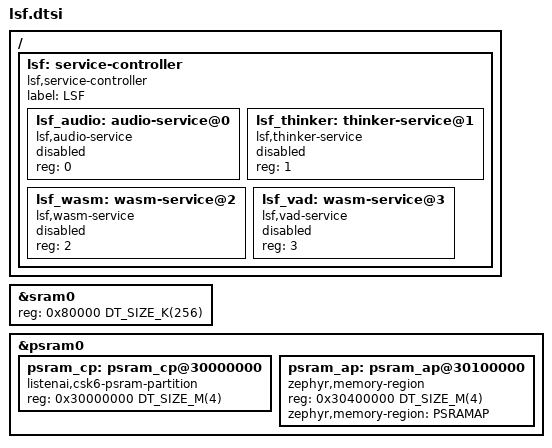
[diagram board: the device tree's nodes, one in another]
/*
 * Copyright(c) 2023 LISTENAI
 * SPDX-License-Identifier: Apache-2.0
 */

#include <mem.h>

/ {
	lsf: service-controller {
		compatible = "lsf,service-controller";
		#address-cells = <1>;
		#size-cells = <0>;
		label = "LSF";

		lsf_audio: audio-service@0 {
			compatible = "lsf,audio-service";
			reg = <0>;
			status = "disabled";
		};

		lsf_thinker: thinker-service@1 {
			compatible = "lsf,thinker-service";
			reg = <1>;
			status = "disabled";
		};

		lsf_wasm: wasm-service@2 {
			compatible = "lsf,wasm-service";
			reg = <2>;
			status = "disabled";
		};

		lsf_vad: wasm-service@3 {
			compatible = "lsf,vad-service";
			reg = <3>;
			status = "disabled";
		};
	};
};

/delete-node/ &psram_ap;
/delete-node/ &psram_cp;
/delete-node/ &psram_share;

&sram0 {
	reg = <0x80000 DT_SIZE_K(256)>;
};

&psram0 {
	psram_cp: psram_cp@30000000 {
		compatible = "listenai,csk6-psram-partition";
		reg = <0x30000000 DT_SIZE_M(4)>;
		status = "okay";
	};

	psram_ap: psram_ap@30100000 {
		compatible = "zephyr,memory-region";
		reg = <0x30400000 DT_SIZE_M(4)>;
		status = "okay";
		zephyr,memory-region = "PSRAMAP";
	};
};
